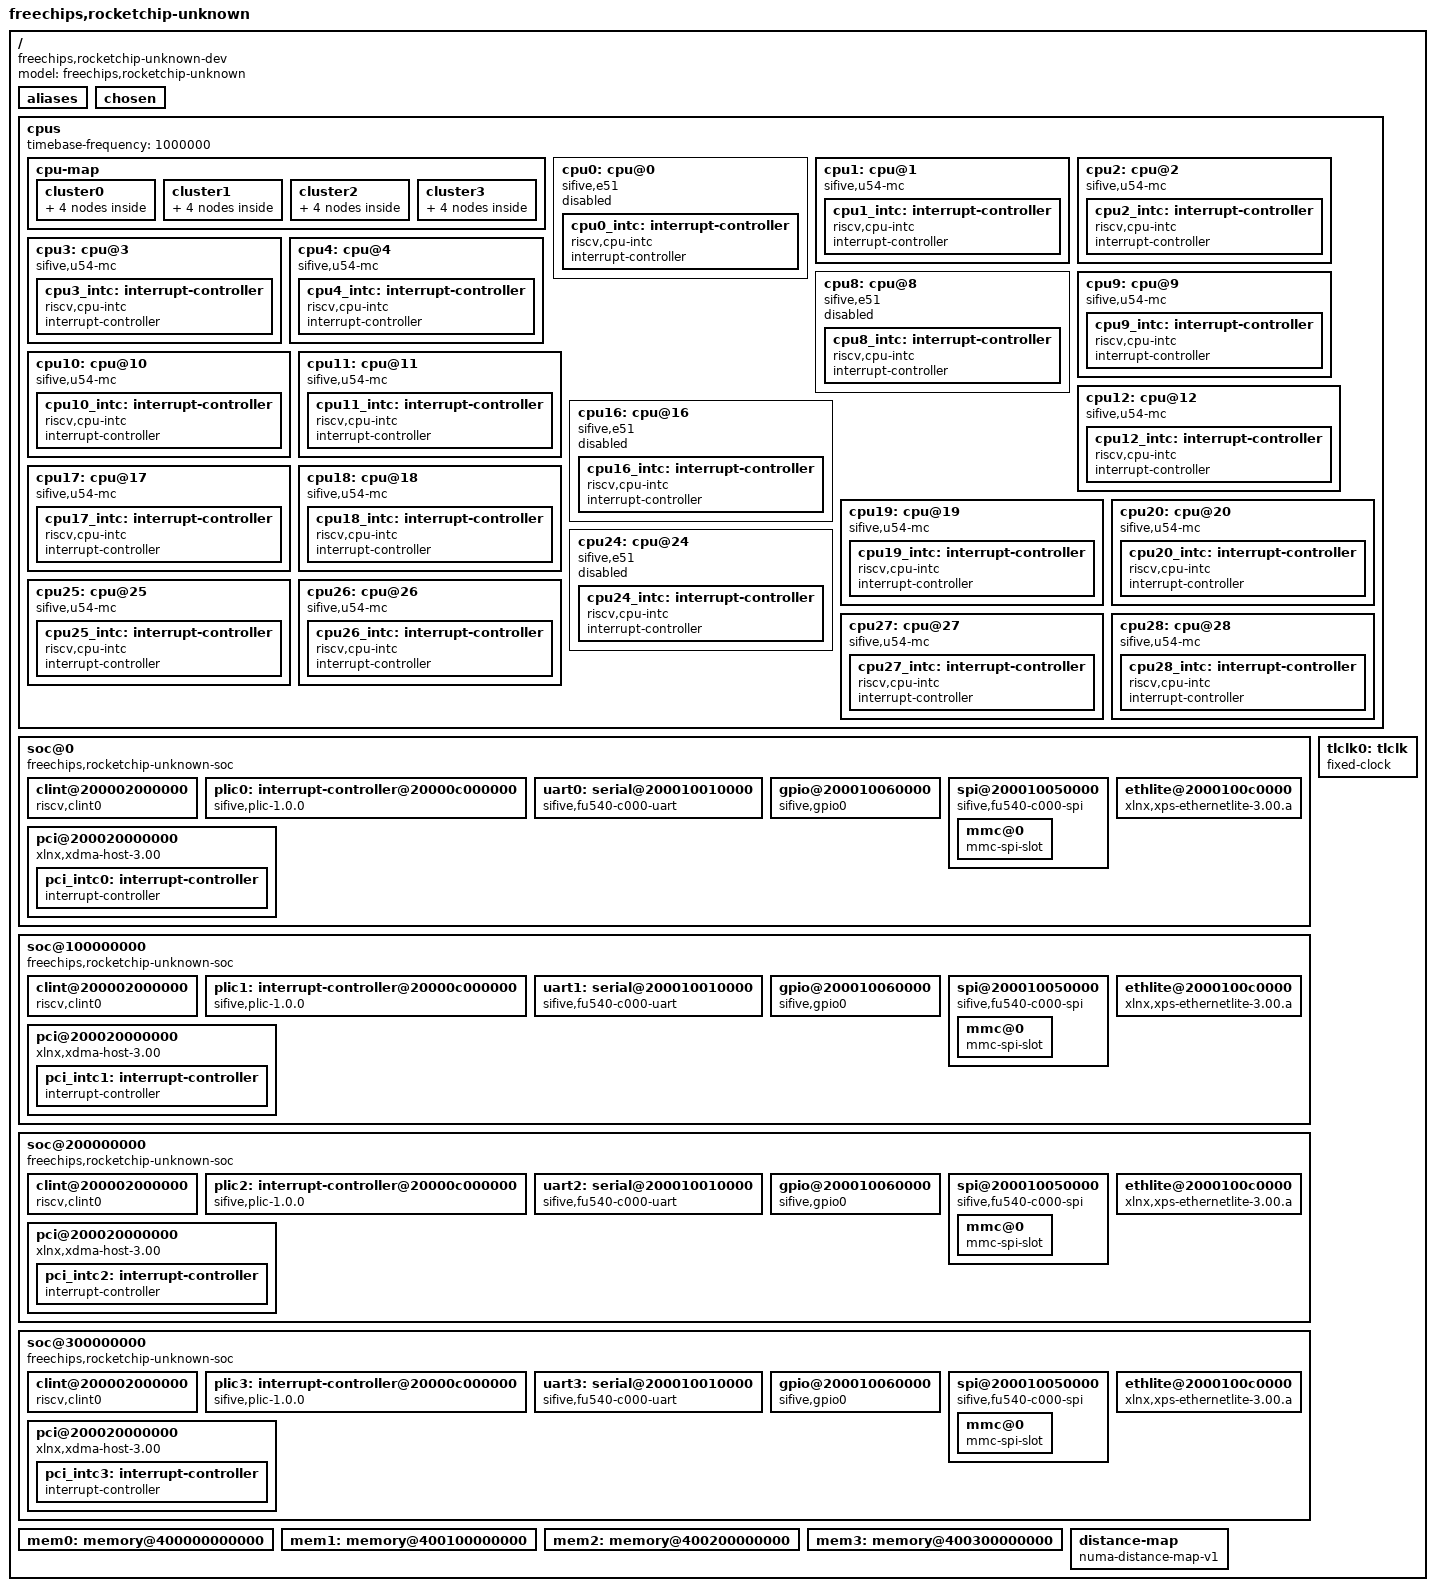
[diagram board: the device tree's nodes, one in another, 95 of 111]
/dts-v1/;

/ {
	#address-cells = <2>;
	#size-cells = <2>;
	compatible = "freechips,rocketchip-unknown-dev";
	model = "freechips,rocketchip-unknown";

	aliases {
		serial0 = &uart0;
		serial1 = &uart1;
		serial2 = &uart2;
		serial3 = &uart3;
	};

	chosen {
		bootargs = "earlycon=sifive,0x200010010000 console=ttySIF0,115200";
	};

	cpus {
		#address-cells = <1>;
		#size-cells = <0>;
		timebase-frequency = <1000000>;

		cpu-map {
			cluster0 {
				core0 {
					cpu = <&cpu1>;
				};
				core1 {
					cpu = <&cpu2>;
				};
				core2 {
					cpu = <&cpu3>;
				};
				core3 {
					cpu = <&cpu4>;
				};
			};

			cluster1 {
				core0 {
					cpu = <&cpu9>;
				};
				core1 {
					cpu = <&cpu10>;
				};
				core2 {
					cpu = <&cpu11>;
				};
				core3 {
					cpu = <&cpu12>;
				};
			};

			cluster2 {
				core0 {
					cpu = <&cpu17>;
				};
				core1 {
					cpu = <&cpu18>;
				};
				core2 {
					cpu = <&cpu19>;
				};
				core3 {
					cpu = <&cpu20>;
				};
			};

			cluster3 {
				core0 {
					cpu = <&cpu25>;
				};
				core1 {
					cpu = <&cpu26>;
				};
				core2 {
					cpu = <&cpu27>;
				};
				core3 {
					cpu = <&cpu28>;
				};
			};
		};
		cpu0: cpu@0 {
			compatible = "sifive,e51", "sifive,bullet0", "riscv";
			device_type = "cpu";
			i-cache-block-size = <0x40>;
			i-cache-sets = <0x80>;
			i-cache-size = <0x4000>;
			reg = <0x0>;
			riscv,isa = "rv64imac";
			status = "disabled";
			numa-node-id = <0>;

			cpu0_intc: interrupt-controller {
				#interrupt-cells = <0x1>;
				compatible = "riscv,cpu-intc";
				interrupt-controller;
			};
		};

		cpu1: cpu@1 {
			compatible = "sifive,u54-mc", "sifive,bullet0", "riscv";
			d-cache-block-size = <0x40>;
			d-cache-sets = <0x40>;
			d-cache-size = <0x8000>;
			d-tlb-sets = <0x1>;
			d-tlb-size = <0x20>;
			device_type = "cpu";
			i-cache-block-size = <0x40>;
			i-cache-sets = <0x40>;
			i-cache-size = <0x8000>;
			i-tlb-sets = <0x1>;
			i-tlb-size = <0x20>;
			mmu-type = "riscv,sv48";
			reg = <0x1>;
			riscv,isa = "rv64imafdc";
			status = "okay";
			tlb-split;
			numa-node-id = <0>;

			cpu1_intc: interrupt-controller {
				#interrupt-cells = <0x1>;
				compatible = "riscv,cpu-intc";
				interrupt-controller;
			};
		};

		cpu2: cpu@2 {
			clock-frequency = <0x0>;
			compatible = "sifive,u54-mc", "sifive,bullet0", "riscv";
			d-cache-block-size = <0x40>;
			d-cache-sets = <0x40>;
			d-cache-size = <0x8000>;
			d-tlb-sets = <0x1>;
			d-tlb-size = <0x20>;
			device_type = "cpu";
			i-cache-block-size = <0x40>;
			i-cache-sets = <0x40>;
			i-cache-size = <0x8000>;
			i-tlb-sets = <0x1>;
			i-tlb-size = <0x20>;
			mmu-type = "riscv,sv48";
			reg = <0x2>;
			riscv,isa = "rv64imafdc";
			status = "okay";
			tlb-split;
			numa-node-id = <0>;

			cpu2_intc: interrupt-controller {
				#interrupt-cells = <0x1>;
				compatible = "riscv,cpu-intc";
				interrupt-controller;
			};
		};

		cpu3: cpu@3 {
			clock-frequency = <0x0>;
			compatible = "sifive,u54-mc", "sifive,bullet0", "riscv";
			d-cache-block-size = <0x40>;
			d-cache-sets = <0x40>;
			d-cache-size = <0x8000>;
			d-tlb-sets = <0x1>;
			d-tlb-size = <0x20>;
			device_type = "cpu";
			i-cache-block-size = <0x40>;
			i-cache-sets = <0x40>;
			i-cache-size = <0x8000>;
			i-tlb-sets = <0x1>;
			i-tlb-size = <0x20>;
			mmu-type = "riscv,sv48";
			reg = <0x3>;
			riscv,isa = "rv64imafdc";
			status = "okay";
			tlb-split;
			numa-node-id = <0>;

			cpu3_intc: interrupt-controller {
				#interrupt-cells = <0x1>;
				compatible = "riscv,cpu-intc";
				interrupt-controller;
			};
		};

		cpu4: cpu@4 {
			clock-frequency = <0x0>;
			compatible = "sifive,u54-mc", "sifive,bullet0", "riscv";
			d-cache-block-size = <0x40>;
			d-cache-sets = <0x40>;
			d-cache-size = <0x8000>;
			d-tlb-sets = <0x1>;
			d-tlb-size = <0x20>;
			device_type = "cpu";
			i-cache-block-size = <0x40>;
			i-cache-sets = <0x40>;
			i-cache-size = <0x8000>;
			i-tlb-sets = <0x1>;
			i-tlb-size = <0x20>;
			mmu-type = "riscv,sv48";
			reg = <0x4>;
			riscv,isa = "rv64imafdc";
			status = "okay";
			tlb-split;
			numa-node-id = <0>;

			cpu4_intc: interrupt-controller {
				#interrupt-cells = <0x1>;
				compatible = "riscv,cpu-intc";
				interrupt-controller;
			};
		};

		cpu8: cpu@8 {
			clock-frequency = <0x0>;
			compatible = "sifive,e51", "sifive,bullet0", "riscv";
			device_type = "cpu";
			i-cache-block-size = <0x40>;
			i-cache-sets = <0x80>;
			i-cache-size = <0x4000>;
			reg = <0x8>;
			riscv,isa = "rv64imac";
			status = "disabled";
			numa-node-id = <1>;

			cpu8_intc:  interrupt-controller {
				#interrupt-cells = <0x1>;
				compatible = "riscv,cpu-intc";
				interrupt-controller;
			};
		};

		cpu9: cpu@9 {
			clock-frequency = <0x0>;
			compatible = "sifive,u54-mc", "sifive,bullet0", "riscv";
			d-cache-block-size = <0x40>;
			d-cache-sets = <0x40>;
			d-cache-size = <0x8000>;
			d-tlb-sets = <0x1>;
			d-tlb-size = <0x20>;
			device_type = "cpu";
			i-cache-block-size = <0x40>;
			i-cache-sets = <0x40>;
			i-cache-size = <0x8000>;
			i-tlb-sets = <0x1>;
			i-tlb-size = <0x20>;
			mmu-type = "riscv,sv48";
			reg = <0x9>;
			riscv,isa = "rv64imafdc";
			status = "okay";
			tlb-split;
			numa-node-id = <1>;

			cpu9_intc: interrupt-controller {
				#interrupt-cells = <0x1>;
				compatible = "riscv,cpu-intc";
				interrupt-controller;
			};
		};

		cpu10: cpu@10 {
			clock-frequency = <0x0>;
			compatible = "sifive,u54-mc", "sifive,bullet0", "riscv";
			d-cache-block-size = <0x40>;
			d-cache-sets = <0x40>;
			d-cache-size = <0x8000>;
			d-tlb-sets = <0x1>;
			d-tlb-size = <0x20>;
			device_type = "cpu";
			i-cache-block-size = <0x40>;
			i-cache-sets = <0x40>;
			i-cache-size = <0x8000>;
			i-tlb-sets = <0x1>;
			i-tlb-size = <0x20>;
			mmu-type = "riscv,sv48";
			reg = <0xa>;
			riscv,isa = "rv64imafdc";
			status = "okay";
			tlb-split;
			numa-node-id = <1>;

			cpu10_intc: interrupt-controller {
				#interrupt-cells = <0x1>;
				compatible = "riscv,cpu-intc";
				interrupt-controller;
			};
		};

		cpu11: cpu@11 {
			clock-frequency = <0x0>;
			compatible = "sifive,u54-mc", "sifive,bullet0", "riscv";
			d-cache-block-size = <0x40>;
			d-cache-sets = <0x40>;
			d-cache-size = <0x8000>;
			d-tlb-sets = <0x1>;
			d-tlb-size = <0x20>;
			device_type = "cpu";
			i-cache-block-size = <0x40>;
			i-cache-sets = <0x40>;
			i-cache-size = <0x8000>;
			i-tlb-sets = <0x1>;
			i-tlb-size = <0x20>;
			mmu-type = "riscv,sv48";
			reg = <0xb>;
			riscv,isa = "rv64imafdc";
			status = "okay";
			tlb-split;
			numa-node-id = <1>;

			cpu11_intc: interrupt-controller {
				#interrupt-cells = <0x1>;
				compatible = "riscv,cpu-intc";
				interrupt-controller;
			};
		};

		cpu12: cpu@12 {
			clock-frequency = <0x0>;
			compatible = "sifive,u54-mc", "sifive,bullet0", "riscv";
			d-cache-block-size = <0x40>;
			d-cache-sets = <0x40>;
			d-cache-size = <0x8000>;
			d-tlb-sets = <0x1>;
			d-tlb-size = <0x20>;
			device_type = "cpu";
			i-cache-block-size = <0x40>;
			i-cache-sets = <0x40>;
			i-cache-size = <0x8000>;
			i-tlb-sets = <0x1>;
			i-tlb-size = <0x20>;
			mmu-type = "riscv,sv48";
			reg = <0xc>;
			riscv,isa = "rv64imafdc";
			status = "okay";
			tlb-split;
			numa-node-id = <1>;

			cpu12_intc: interrupt-controller {
				#interrupt-cells = <0x1>;
				compatible = "riscv,cpu-intc";
				interrupt-controller;
			};
		};

		cpu16: cpu@16 {
			clock-frequency = <0x0>;
			compatible = "sifive,e51", "sifive,bullet0", "riscv";
			device_type = "cpu";
			i-cache-block-size = <0x40>;
			i-cache-sets = <0x80>;
			i-cache-size = <0x4000>;
			reg = <16>;
			riscv,isa = "rv64imac";
			status = "disabled";
			numa-node-id = <2>;

			cpu16_intc:  interrupt-controller {
				#interrupt-cells = <0x1>;
				compatible = "riscv,cpu-intc";
				interrupt-controller;
			};
		};

		cpu17: cpu@17 {
			clock-frequency = <0x0>;
			compatible = "sifive,u54-mc", "sifive,bullet0", "riscv";
			d-cache-block-size = <0x40>;
			d-cache-sets = <0x40>;
			d-cache-size = <0x8000>;
			d-tlb-sets = <0x1>;
			d-tlb-size = <0x20>;
			device_type = "cpu";
			i-cache-block-size = <0x40>;
			i-cache-sets = <0x40>;
			i-cache-size = <0x8000>;
			i-tlb-sets = <0x1>;
			i-tlb-size = <0x20>;
			mmu-type = "riscv,sv48";
			reg = <17>;
			riscv,isa = "rv64imafdc";
			status = "okay";
			tlb-split;
			numa-node-id = <2>;

			cpu17_intc: interrupt-controller {
				#interrupt-cells = <0x1>;
				compatible = "riscv,cpu-intc";
				interrupt-controller;
			};
		};

		cpu18: cpu@18 {
			clock-frequency = <0x0>;
			compatible = "sifive,u54-mc", "sifive,bullet0", "riscv";
			d-cache-block-size = <0x40>;
			d-cache-sets = <0x40>;
			d-cache-size = <0x8000>;
			d-tlb-sets = <0x1>;
			d-tlb-size = <0x20>;
			device_type = "cpu";
			i-cache-block-size = <0x40>;
			i-cache-sets = <0x40>;
			i-cache-size = <0x8000>;
			i-tlb-sets = <0x1>;
			i-tlb-size = <0x20>;
			mmu-type = "riscv,sv48";
			reg = <18>;
			riscv,isa = "rv64imafdc";
			status = "okay";
			tlb-split;
			numa-node-id = <2>;

			cpu18_intc: interrupt-controller {
				#interrupt-cells = <0x1>;
				compatible = "riscv,cpu-intc";
				interrupt-controller;
			};
		};

		cpu19: cpu@19 {
			clock-frequency = <0x0>;
			compatible = "sifive,u54-mc", "sifive,bullet0", "riscv";
			d-cache-block-size = <0x40>;
			d-cache-sets = <0x40>;
			d-cache-size = <0x8000>;
			d-tlb-sets = <0x1>;
			d-tlb-size = <0x20>;
			device_type = "cpu";
			i-cache-block-size = <0x40>;
			i-cache-sets = <0x40>;
			i-cache-size = <0x8000>;
			i-tlb-sets = <0x1>;
			i-tlb-size = <0x20>;
			mmu-type = "riscv,sv48";
			reg = <19>;
			riscv,isa = "rv64imafdc";
			status = "okay";
			tlb-split;
			numa-node-id = <2>;

			cpu19_intc: interrupt-controller {
				#interrupt-cells = <0x1>;
				compatible = "riscv,cpu-intc";
				interrupt-controller;
			};
		};

		cpu20: cpu@20 {
			clock-frequency = <0x0>;
			compatible = "sifive,u54-mc", "sifive,bullet0", "riscv";
			d-cache-block-size = <0x40>;
			d-cache-sets = <0x40>;
			d-cache-size = <0x8000>;
			d-tlb-sets = <0x1>;
			d-tlb-size = <0x20>;
			device_type = "cpu";
			i-cache-block-size = <0x40>;
			i-cache-sets = <0x40>;
			i-cache-size = <0x8000>;
			i-tlb-sets = <0x1>;
			i-tlb-size = <0x20>;
			mmu-type = "riscv,sv48";
			reg = <20>;
			riscv,isa = "rv64imafdc";
			status = "okay";
			tlb-split;
			numa-node-id = <2>;

			cpu20_intc: interrupt-controller {
				#interrupt-cells = <0x1>;
				compatible = "riscv,cpu-intc";
				interrupt-controller;
			};
		};

		cpu24: cpu@24 {
			clock-frequency = <0x0>;
			compatible = "sifive,e51", "sifive,bullet0", "riscv";
			device_type = "cpu";
			i-cache-block-size = <0x40>;
			i-cache-sets = <0x80>;
			i-cache-size = <0x4000>;
			reg = <24>;
			riscv,isa = "rv64imac";
			status = "disabled";
			numa-node-id = <3>;

			cpu24_intc:  interrupt-controller {
				#interrupt-cells = <0x1>;
				compatible = "riscv,cpu-intc";
				interrupt-controller;
			};
		};

		cpu25: cpu@25 {
			clock-frequency = <0x0>;
			compatible = "sifive,u54-mc", "sifive,bullet0", "riscv";
			d-cache-block-size = <0x40>;
			d-cache-sets = <0x40>;
			d-cache-size = <0x8000>;
			d-tlb-sets = <0x1>;
			d-tlb-size = <0x20>;
			device_type = "cpu";
			i-cache-block-size = <0x40>;
			i-cache-sets = <0x40>;
			i-cache-size = <0x8000>;
			i-tlb-sets = <0x1>;
			i-tlb-size = <0x20>;
			mmu-type = "riscv,sv48";
			reg = <25>;
			riscv,isa = "rv64imafdc";
			status = "okay";
			tlb-split;
			numa-node-id = <3>;

			cpu25_intc: interrupt-controller {
				#interrupt-cells = <0x1>;
				compatible = "riscv,cpu-intc";
				interrupt-controller;
			};
		};

		cpu26: cpu@26 {
			clock-frequency = <0x0>;
			compatible = "sifive,u54-mc", "sifive,bullet0", "riscv";
			d-cache-block-size = <0x40>;
			d-cache-sets = <0x40>;
			d-cache-size = <0x8000>;
			d-tlb-sets = <0x1>;
			d-tlb-size = <0x20>;
			device_type = "cpu";
			i-cache-block-size = <0x40>;
			i-cache-sets = <0x40>;
			i-cache-size = <0x8000>;
			i-tlb-sets = <0x1>;
			i-tlb-size = <0x20>;
			mmu-type = "riscv,sv48";
			reg = <26>;
			riscv,isa = "rv64imafdc";
			status = "okay";
			tlb-split;
			numa-node-id = <3>;

			cpu26_intc: interrupt-controller {
				#interrupt-cells = <0x1>;
				compatible = "riscv,cpu-intc";
				interrupt-controller;
			};
		};

		cpu27: cpu@27 {
			clock-frequency = <0x0>;
			compatible = "sifive,u54-mc", "sifive,bullet0", "riscv";
			d-cache-block-size = <0x40>;
			d-cache-sets = <0x40>;
			d-cache-size = <0x8000>;
			d-tlb-sets = <0x1>;
			d-tlb-size = <0x20>;
			device_type = "cpu";
			i-cache-block-size = <0x40>;
			i-cache-sets = <0x40>;
			i-cache-size = <0x8000>;
			i-tlb-sets = <0x1>;
			i-tlb-size = <0x20>;
			mmu-type = "riscv,sv48";
			reg = <27>;
			riscv,isa = "rv64imafdc";
			status = "okay";
			tlb-split;
			numa-node-id = <3>;

			cpu27_intc: interrupt-controller {
				#interrupt-cells = <0x1>;
				compatible = "riscv,cpu-intc";
				interrupt-controller;
			};
		};

		cpu28: cpu@28 {
			clock-frequency = <0x0>;
			compatible = "sifive,u54-mc", "sifive,bullet0", "riscv";
			d-cache-block-size = <0x40>;
			d-cache-sets = <0x40>;
			d-cache-size = <0x8000>;
			d-tlb-sets = <0x1>;
			d-tlb-size = <0x20>;
			device_type = "cpu";
			i-cache-block-size = <0x40>;
			i-cache-sets = <0x40>;
			i-cache-size = <0x8000>;
			i-tlb-sets = <0x1>;
			i-tlb-size = <0x20>;
			mmu-type = "riscv,sv48";
			reg = <28>;
			riscv,isa = "rv64imafdc";
			status = "okay";
			tlb-split;
			numa-node-id = <3>;

			cpu28_intc: interrupt-controller {
				#interrupt-cells = <0x1>;
				compatible = "riscv,cpu-intc";
				interrupt-controller;
			};
		};
	};

	soc@0 {
		#address-cells = <0x2>;
		#size-cells = <0x2>;
		compatible = "freechips,rocketchip-unknown-soc", "simple-bus";
		ranges = <0x2000 0x0 0x2000 0x0 0x1 0x0>;

		clint@200002000000 {
			compatible = "riscv,clint0";
			interrupts-extended = <&cpu0_intc 0x3 &cpu0_intc 0x7
                                               &cpu1_intc 0x3 &cpu1_intc 0x7
                                               &cpu2_intc 0x3 &cpu2_intc 0x7
                                               &cpu3_intc 0x3 &cpu3_intc 0x7
                                               &cpu4_intc 0x3 &cpu4_intc 0x7>;
			reg = <0x2000 0x2000000 0x0 0x10000>;
			reg-names = "control";
			numa-node-id = <0>;
		};

		plic0: interrupt-controller@20000c000000 {
			#interrupt-cells = <0x1>;
			compatible = "sifive,plic-1.0.0";
			reg = <0x2000 0xc000000 0x0 0x4000000>;
			riscv,ndev = <52>;
			interrupt-controller;
			interrupts-extended = <&cpu0_intc 11
                                               &cpu1_intc 11 &cpu1_intc 9
                                               &cpu2_intc 11 &cpu2_intc 9
                                               &cpu3_intc 11 &cpu3_intc 9
                                               &cpu4_intc 11 &cpu4_intc 9>;
			reg-names = "control";
			riscv,max-priority = <7>;
			numa-node-id = <0>;
		};

		uart0: serial@200010010000 {
			compatible = "sifive,fu540-c000-uart", "sifive,uart0";
			reg = <0x2000 0x10010000 0x0 0x1000>;
			interrupt-parent = <&plic0>;
			clocks = <&tlclk0>;
			status = "okay";
			interrupts = <5>;
			numa-node-id = <0>;
		};

		gpio@200010060000 {
			#gpio-cells = <0x2>;
			#interrupt-cells = <0x2>;
			compatible = "sifive,gpio0", "sifive,gpio1";
			gpio-controller;
			interrupt-controller;
			interrupt-parent = <&plic0>;
			interrupts = <6 7 8 9 10 11 12 13 14 15 16 17 18 19 20 21>;
			reg = <0x2000 0x10060000 0x0 0x1000>;
			reg-names = "control";
			numa-node-id = <0>;
		};

		spi@200010050000 {
			compatible = "sifive,fu540-c000-spi", "sifive,spi0";
			reg = <0x2000 0x10050000 0x0 0x1000>;
			interrupt-parent = <&plic0>;
			interrupts = <26>;
			clocks = <&tlclk0>;
			#address-cells = <0x1>;
			#size-cells = <0x0>;
			numa-node-id = <0>;

			mmc@0 {
				compatible = "mmc-spi-slot";
				reg = <0x0>;
				spi-max-frequency = <5000000>;
				voltage-ranges = <0xce4 0xce4>;
				disable-wp;
			};
		};

		ethlite@2000100c0000 {
			compatible = "xlnx,xps-ethernetlite-3.00.a";
			device_type = "network";
			interrupt-parent = <&plic0>;
			interrupts = <27>;
			reg = <0x2000 0x100c0000 0x0 0x2000>;
			xlnx,rx-ping-pong = <1>;
			xlnx,tx-ping-pong = <1>;
			local-mac-address = [ 68 05 CA 88 63 00 ];
			numa-node-id = <0>;
		};

		pci@200020000000 {
			#address-cells = <0x3>;
			#interrupt-cells = <0x1>;
			#size-cells = <0x2>;
			compatible = "xlnx,xdma-host-3.00";
			device_type = "pci";
			interrupt-map = <0x0 0x0 0x0 0x1
                                         &pci_intc0 0x1 0x0 0x0 0x0 0x2
                                         &pci_intc0 0x2 0x0 0x0 0x0 0x3
                                         &pci_intc0 0x3 0x0 0x0 0x0 0x4
                                         &pci_intc0 0x4>;
			interrupt-map-mask = <0x0 0x0 0x0 0x7>;
			interrupt-names = "misc", "msi0", "msi1";
			interrupt-parent = <&plic0>;
			interrupts = <45 46 47>;
			ranges = <0x2000000 0x0 0x0 0x2000 0x40000000 0x0 0x40000000>;
			reg = <0x2000 0x20000000 0x0 0x4000000>;
			reg-names = "control";
			numa-node-id = <0>;

			pci_intc0: interrupt-controller {
				#address-cells = <0x0>;
				#interrupt-cells = <0x1>;
				interrupt-controller;
			};
		};
	};

	soc@100000000 {
		#address-cells = <0x2>;
		#size-cells = <0x2>;
		compatible = "freechips,rocketchip-unknown-soc", "simple-bus";
		ranges = <0x2000 0x0 0x2001 0x0 0x1 0x0>;

		clint@200002000000 {
			compatible = "riscv,clint0";
			interrupts-extended = <&cpu8_intc  0x3 &cpu8_intc  0x7
                                               &cpu9_intc  0x3 &cpu9_intc  0x7
                                               &cpu10_intc 0x3 &cpu10_intc 0x7
                                               &cpu11_intc 0x3 &cpu11_intc 0x7
                                               &cpu12_intc 0x3 &cpu12_intc 0x7>;
			reg = <0x2000 0x2000000 0x0 0x10000>;
			reg-names = "control";
			numa-node-id = <1>;
		};

		plic1: interrupt-controller@20000c000000 {
			#interrupt-cells = <0x1>;
			compatible = "sifive,plic-1.0.0";
			reg = <0x2000 0xc000000 0x0 0x4000000>;
			riscv,ndev = <52>;
			interrupt-controller;
			interrupts-extended = <&cpu8_intc 11
                                               &cpu9_intc 11 &cpu9_intc 9
                                               &cpu10_intc 11 &cpu10_intc 9
                                               &cpu11_intc 11 &cpu11_intc 9
                                               &cpu12_intc 11 &cpu12_intc 9>;
			reg-names = "control";
			riscv,max-priority = <7>;
			numa-node-id = <1>;
		};

		uart1: serial@200010010000 {
			compatible = "sifive,fu540-c000-uart", "sifive,uart0";
			reg = <0x2000 0x10010000 0x0 0x1000>;
			interrupt-parent = <&plic1>;
			clocks = <&tlclk0>;
			status = "okay";
			interrupts = <5>;
			numa-node-id = <1>;
		};

		gpio@200010060000 {
			#gpio-cells = <0x2>;
			#interrupt-cells = <0x2>;
			compatible = "sifive,gpio0", "sifive,gpio1";
			gpio-controller;
			interrupt-controller;
			interrupt-parent = <&plic1>;
			interrupts = <6 7 8 9 10 11 12 13 14 15 16 17 18 19 20 21>;
			reg = <0x2000 0x10060000 0x0 0x1000>;
			reg-names = "control";
			numa-node-id = <1>;
		};

		spi@200010050000 {
			compatible = "sifive,fu540-c000-spi", "sifive,spi0";
			reg = <0x2000 0x10050000 0x0 0x1000>;
			interrupt-parent = <&plic1>;
			interrupts = <26>;
			clocks = <&tlclk0>;
			#address-cells = <0x1>;
			#size-cells = <0x0>;
			numa-node-id = <1>;

			mmc@0 {
				compatible = "mmc-spi-slot";
				reg = <0x0>;
				spi-max-frequency = <5000000>;
				voltage-ranges = <0xce4 0xce4>;
				disable-wp;
			};
		};

		ethlite@2000100c0000 {
			compatible = "xlnx,xps-ethernetlite-3.00.a";
			device_type = "network";
			interrupt-parent = <&plic1>;
			interrupts = <27>;
			reg = <0x2000 0x100c0000 0x0 0x2000>;
			xlnx,rx-ping-pong = <1>;
			xlnx,tx-ping-pong = <1>;
			local-mac-address = [ 68 05 CA 88 63 01 ];
			numa-node-id = <1>;
		};

		pci@200020000000 {
			#address-cells = <0x3>;
			#interrupt-cells = <0x1>;
			#size-cells = <0x2>;
			compatible = "xlnx,xdma-host-3.00";
			device_type = "pci";
			interrupt-map = <0x0 0x0 0x0 0x1
                                         &pci_intc1 0x1 0x0 0x0 0x0 0x2
                                         &pci_intc1 0x2 0x0 0x0 0x0 0x3
                                         &pci_intc1 0x3 0x0 0x0 0x0 0x4
                                         &pci_intc1 0x4>;
			interrupt-map-mask = <0x0 0x0 0x0 0x7>;
			interrupt-names = "misc", "msi0", "msi1";
			interrupt-parent = <&plic1>;
			interrupts = <45 46 47>;
			ranges = <0x2000000 0x0 0x0 0x2000 0x40000000 0x0 0x40000000>;
			reg = <0x2000 0x20000000 0x0 0x4000000>;
			reg-names = "control";
			numa-node-id = <1>;

			pci_intc1: interrupt-controller {
				#address-cells = <0x0>;
				#interrupt-cells = <0x1>;
				interrupt-controller;
			};
		};
	};

	soc@200000000 {
		#address-cells = <0x2>;
		#size-cells = <0x2>;
		compatible = "freechips,rocketchip-unknown-soc", "simple-bus";
		ranges = <0x2000 0x0 0x2002 0x0 0x1 0x0>;

		clint@200002000000 {
			compatible = "riscv,clint0";
			interrupts-extended = <&cpu16_intc 0x3 &cpu16_intc 0x7
                                               &cpu17_intc 0x3 &cpu17_intc 0x7
                                               &cpu18_intc 0x3 &cpu18_intc 0x7
                                               &cpu19_intc 0x3 &cpu19_intc 0x7
                                               &cpu20_intc 0x3 &cpu20_intc 0x7>;
			reg = <0x2000 0x2000000 0x0 0x10000>;
			reg-names = "control";
			numa-node-id = <2>;
		};

		plic2: interrupt-controller@20000c000000 {
			#interrupt-cells = <0x1>;
			compatible = "sifive,plic-1.0.0";
			reg = <0x2000 0xc000000 0x0 0x4000000>;
			riscv,ndev = <52>;
			interrupt-controller;
			interrupts-extended = <&cpu16_intc 11
                                               &cpu17_intc 11 &cpu17_intc 9
                                               &cpu18_intc 11 &cpu18_intc 9
                                               &cpu19_intc 11 &cpu19_intc 9
                                               &cpu20_intc 11 &cpu20_intc 9>;
			reg-names = "control";
			riscv,max-priority = <7>;
			numa-node-id = <2>;
		};

		uart2: serial@200010010000 {
			compatible = "sifive,fu540-c000-uart", "sifive,uart0";
			reg = <0x2000 0x10010000 0x0 0x1000>;
			interrupt-parent = <&plic2>;
			clocks = <&tlclk0>;
			status = "okay";
			interrupts = <5>;
			numa-node-id = <2>;
		};

		gpio@200010060000 {
			#gpio-cells = <0x2>;
			#interrupt-cells = <0x2>;
			compatible = "sifive,gpio0", "sifive,gpio1";
			gpio-controller;
			interrupt-controller;
			interrupt-parent = <&plic2>;
			interrupts = <6 7 8 9 10 11 12 13 14 15 16 17 18 19 20 21>;
			reg = <0x2000 0x10060000 0x0 0x1000>;
			reg-names = "control";
			numa-node-id = <2>;
		};

		spi@200010050000 {
			compatible = "sifive,fu540-c000-spi", "sifive,spi0";
			reg = <0x2000 0x10050000 0x0 0x1000>;
			interrupt-parent = <&plic2>;
			interrupts = <26>;
			clocks = <&tlclk0>;
			#address-cells = <0x1>;
			#size-cells = <0x0>;
			numa-node-id = <2>;

			mmc@0 {
				compatible = "mmc-spi-slot";
				reg = <0x0>;
				spi-max-frequency = <5000000>;
				voltage-ranges = <0xce4 0xce4>;
				disable-wp;
			};
		};

		ethlite@2000100c0000 {
			compatible = "xlnx,xps-ethernetlite-3.00.a";
			device_type = "network";
			interrupt-parent = <&plic2>;
			interrupts = <27>;
			reg = <0x2000 0x100c0000 0x0 0x2000>;
			xlnx,rx-ping-pong = <1>;
			xlnx,tx-ping-pong = <1>;
			local-mac-address = [ 68 05 CA 88 63 02 ];
			numa-node-id = <2>;
		};

		pci@200020000000 {
			#address-cells = <0x3>;
			#interrupt-cells = <0x1>;
			#size-cells = <0x2>;
			compatible = "xlnx,xdma-host-3.00";
			device_type = "pci";
			interrupt-map = <0x0 0x0 0x0 0x1
                                         &pci_intc2 0x1 0x0 0x0 0x0 0x2
                                         &pci_intc2 0x2 0x0 0x0 0x0 0x3
                                         &pci_intc2 0x3 0x0 0x0 0x0 0x4
                                         &pci_intc2 0x4>;
			interrupt-map-mask = <0x0 0x0 0x0 0x7>;
			interrupt-names = "misc", "msi0", "msi1";
			interrupt-parent = <&plic2>;
			interrupts = <45 46 47>;
			ranges = <0x2000000 0x0 0x0 0x2000 0x40000000 0x0 0x40000000>;
			reg = <0x2000 0x20000000 0x0 0x4000000>;
			reg-names = "control";
			numa-node-id = <2>;

			pci_intc2: interrupt-controller {
				#address-cells = <0x0>;
				#interrupt-cells = <0x1>;
				interrupt-controller;
			};
		};
	};

	soc@300000000 {
		#address-cells = <0x2>;
		#size-cells = <0x2>;
		compatible = "freechips,rocketchip-unknown-soc", "simple-bus";
		ranges = <0x2000 0x0 0x2003 0x0 0x1 0x0>;

		clint@200002000000 {
			compatible = "riscv,clint0";
			interrupts-extended = <&cpu24_intc 0x3 &cpu24_intc 0x7
                                               &cpu25_intc 0x3 &cpu25_intc 0x7
                                               &cpu26_intc 0x3 &cpu26_intc 0x7
                                               &cpu27_intc 0x3 &cpu27_intc 0x7
                                               &cpu28_intc 0x3 &cpu28_intc 0x7>;
			reg = <0x2000 0x2000000 0x0 0x10000>;
			reg-names = "control";
			numa-node-id = <3>;
		};

		plic3: interrupt-controller@20000c000000 {
			#interrupt-cells = <0x1>;
			compatible = "sifive,plic-1.0.0";
			reg = <0x2000 0xc000000 0x0 0x4000000>;
			riscv,ndev = <52>;
			interrupt-controller;
			interrupts-extended = <&cpu24_intc 11
                                               &cpu25_intc 11 &cpu25_intc 0x9
                                               &cpu26_intc 11 &cpu26_intc 0x9
                                               &cpu27_intc 11 &cpu27_intc 0x9
                                               &cpu28_intc 11 &cpu28_intc 0x9>;
			reg-names = "control";
			riscv,max-priority = <7>;
			numa-node-id = <3>;
		};

		uart3: serial@200010010000 {
			compatible = "sifive,fu540-c000-uart", "sifive,uart0";
			reg = <0x2000 0x10010000 0x0 0x1000>;
			interrupt-parent = <&plic3>;
			clocks = <&tlclk0>;
			status = "okay";
			interrupts = <5>;
			numa-node-id = <3>;
		};

		gpio@200010060000 {
			#gpio-cells = <0x2>;
			#interrupt-cells = <0x2>;
			compatible = "sifive,gpio0", "sifive,gpio1";
			gpio-controller;
			interrupt-controller;
			interrupt-parent = <&plic3>;
			interrupts = <6 7 8 9 10 11 12 13 14 15 16 17 18 19 20 21>;
			reg = <0x2000 0x10060000 0x0 0x1000>;
			reg-names = "control";
			numa-node-id = <3>;
		};

		spi@200010050000 {
			compatible = "sifive,fu540-c000-spi", "sifive,spi0";
			reg = <0x2000 0x10050000 0x0 0x1000>;
			interrupt-parent = <&plic3>;
			interrupts = <26>;
			clocks = <&tlclk0>;
			#address-cells = <0x1>;
			#size-cells = <0x0>;
			numa-node-id = <3>;

			mmc@0 {
				compatible = "mmc-spi-slot";
				reg = <0x0>;
				spi-max-frequency = <5000000>;
				voltage-ranges = <0xce4 0xce4>;
				disable-wp;
			};
		};

		ethlite@2000100c0000 {
			compatible = "xlnx,xps-ethernetlite-3.00.a";
			device_type = "network";
			interrupt-parent = <&plic3>;
			interrupts = <27>;
			reg = <0x2000 0x100c0000 0x0 0x2000>;
			xlnx,rx-ping-pong = <1>;
			xlnx,tx-ping-pong = <1>;
			local-mac-address = [ 68 05 CA 88 63 03 ];
			numa-node-id = <3>;
		};

		pci@200020000000 {
			#address-cells = <0x3>;
			#interrupt-cells = <0x1>;
			#size-cells = <0x2>;
			compatible = "xlnx,xdma-host-3.00";
			device_type = "pci";
			interrupt-map = <0x0 0x0 0x0 0x1
                                         &pci_intc3 0x1 0x0 0x0 0x0 0x2
                                         &pci_intc3 0x2 0x0 0x0 0x0 0x3
                                         &pci_intc3 0x3 0x0 0x0 0x0 0x4
                                         &pci_intc3 0x4>;
			interrupt-map-mask = <0x0 0x0 0x0 0x7>;
			interrupt-names = "misc", "msi0", "msi1";
			interrupt-parent = <&plic3>;
			interrupts = <45 46 47>;
			ranges = <0x2000000 0x0 0x0 0x2000 0x40000000 0x0 0x40000000>;
			reg = <0x2000 0x20000000 0x0 0x4000000>;
			reg-names = "control";
			numa-node-id = <3>;

			pci_intc3: interrupt-controller {
				#address-cells = <0x0>;
				#interrupt-cells = <0x1>;
				interrupt-controller;
			};
		};
	};

	mem0: memory@400000000000 {
		device_type = "memory";
		reg = <0x4000 0x0 0x0 0x80000000>;
		numa-node-id = <0>;
	};

	mem1: memory@400100000000 {
		device_type = "memory";
		reg = <0x4001 0x0 0x0 0x80000000>;
		numa-node-id = <1>;
	};

	mem2: memory@400200000000 {
		device_type = "memory";
		reg = <0x4002 0x0 0x0 0x80000000>;
		numa-node-id = <2>;
	};

	mem3: memory@400300000000 {
		device_type = "memory";
		reg = <0x4003 0x0 0x0 0x80000000>;
		numa-node-id = <3>;
	};

	distance-map {
		compatible = "numa-distance-map-v1";
		distance-matrix = <0 0 10>,
				  <0 1 15>,
				  <0 2 15>,
				  <0 3 15>,
				  <1 0 15>,
				  <1 1 10>,
				  <1 2 15>,
				  <1 3 15>,
				  <2 0 15>,
				  <2 1 15>,
				  <2 2 10>,
				  <2 3 15>,
				  <3 0 15>,
				  <3 1 15>,
				  <3 2 15>,
				  <3 3 10>;
	};

	tlclk0: tlclk {
		#clock-cells = <0>;
		compatible = "fixed-clock";
		clock-frequency = <100000000>;
		clock-output-names = "tlclk";
	};
};
